# CAN2 register map
Registers from a debugger description file.
Registers are 32-bit, access not given, no defined reset value unless marked. A register's access mark holds for its fields unless they carry their own. Addresses are absolute; registers are grouped by the start of their names; lines under a group give offsets from that group; [hi:lo] are bit positions; {n}, {i} and the like mark numbered series; 'fields as' and 'values as' point back to an identical list; <NAME> marks a mode.

## CAN2
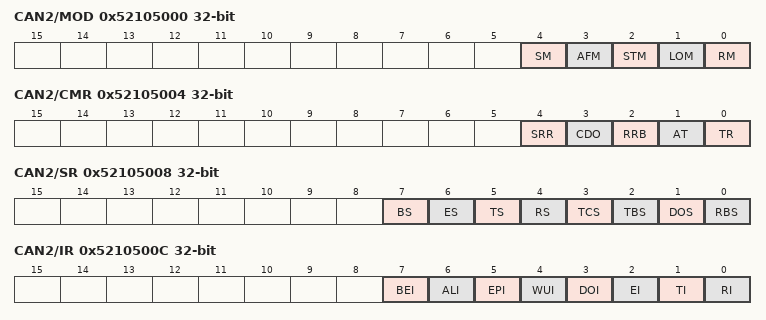
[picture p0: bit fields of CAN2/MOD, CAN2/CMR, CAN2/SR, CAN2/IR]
0x52105000 CAN2/MOD
  [4] SM, [3] AFM, [2] STM, [1] LOM, [0] RM
0x52105004 CAN2/CMR wo
  [4] SRR, [3] CDO, [2] RRB, [1] AT, [0] TR
0x52105008 CAN2/SR ro
  [7] BS, [6] ES, [5] TS, [4] RS, [3] TCS, [2] TBS, [1] DOS, [0] RBS
0x5210500C CAN2/IR ro
  [7] BEI, [6] ALI, [5] EPI, [4] WUI, [3] DOI, [2] EI, [1] TI, [0] RI
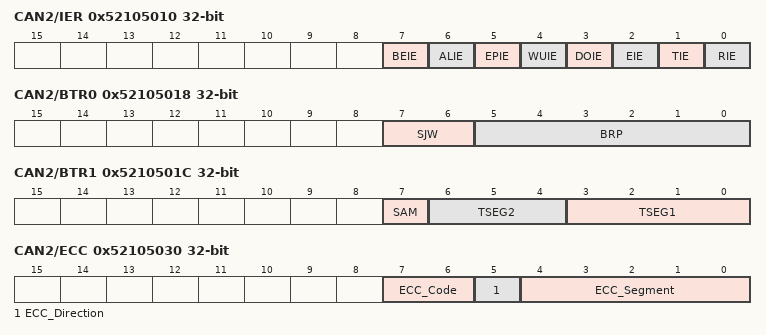
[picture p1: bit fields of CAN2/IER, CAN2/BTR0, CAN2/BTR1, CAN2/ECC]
0x52105010 CAN2/IER
  [7] BEIE, [6] ALIE, [5] EPIE, [4] WUIE, [3] DOIE, [2] EIE, [1] TIE, [0] RIE
0x52105018 CAN2/BTR0
  [7:6] SJW, [5:0] BRP
0x5210501C CAN2/BTR1
  [7] SAM, [6:4] TSEG2, [3:0] TSEG1
0x52105020 CAN2/OCR
  [1:0] OCMODE
0x5210502C CAN2/ALC ro
  [4:0] ALC
0x52105030 CAN2/ECC ro
  [7:6] ECC_Code, [5] ECC_Direction, [4:0] ECC_Segment
0x52105034 CAN2/EWLR
  [7:0] EWLR
0x52105038 CAN2/RXERR
  [7:0] RXERR
0x5210503C CAN2/TXERR
  [7:0] TXERR
{0x52105040+4i} CAN2/WrTransmitBuffer_{i} wo (i=0..12)
  [7:0] WrTransmitBuffer
{0x52105040+4i} CAN2/RdReceiveBuffer_{i} ro (i=0..12)
  [7:0] RdReceiveBuffer
{0x52105040+4i} CAN2/ACR{i} (i=0..3)
  [7:0] ACR
{0x52105050+4i} CAN2/AMR{i} (i=0..3)
  [7:0] AMR
0x52105074 CAN2/RMC ro
  [4:0] RMC
0x52105078 CAN2/RBSA
  [5:0] RBSA
{0x52105080+4i} CAN2/ReceiveFifo_{i} (i=0..63)
  [7:0] ReceiveFifo
{0x52105180+4i} CAN2/RdTransmitBuffer_{i} ro (i=0..12)
  [7:0] RdTransmitBuffer
{0x52105440+4i} CAN2/SyncTransmitBuffer_{i} (i=0..12)
  [7:0] SyncTransmitBuffer
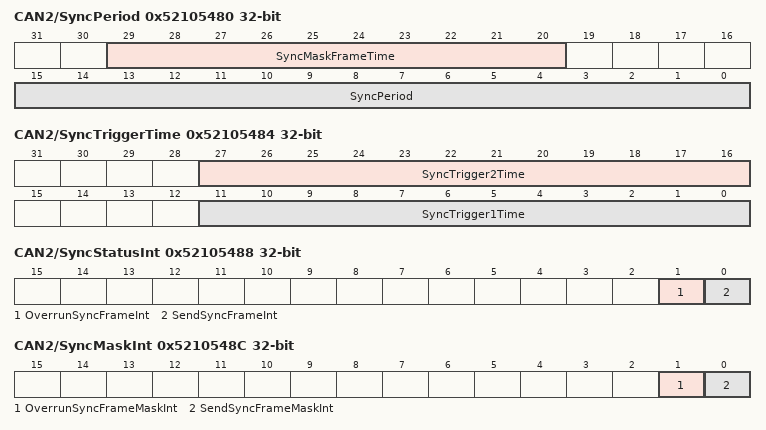
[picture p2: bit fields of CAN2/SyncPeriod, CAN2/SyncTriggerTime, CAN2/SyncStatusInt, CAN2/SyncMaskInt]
0x52105480 CAN2/SyncPeriod
  [29:20] SyncMaskFrameTime, [15:0] SyncPeriod
0x52105484 CAN2/SyncTriggerTime
  [27:16] SyncTrigger2Time, [11:0] SyncTrigger1Time
0x52105488 CAN2/SyncStatusInt ro
  [1] OverrunSyncFrameInt, [0] SendSyncFrameInt
0x5210548C CAN2/SyncMaskInt
  [1] OverrunSyncFrameMaskInt, [0] SendSyncFrameMaskInt
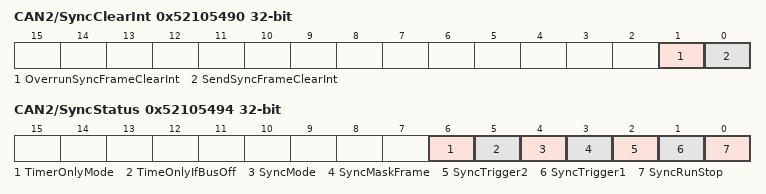
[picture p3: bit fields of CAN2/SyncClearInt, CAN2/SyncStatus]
0x52105490 CAN2/SyncClearInt
  [1] OverrunSyncFrameClearInt, [0] SendSyncFrameClearInt
0x52105494 CAN2/SyncStatus
  [6] TimerOnlyMode, [5] TimeOnlyIfBusOff, [4] SyncMode, [3] SyncMaskFrame ro, [2] SyncTrigger2 ro, [1] SyncTrigger1 ro, [0] SyncRunStop ro
0x52105498 CAN2/SyncClearSetRunStop wo
  [31:0] SyncClearSetRunStop
0x5210549C CAN2/SyncClearSetTrigger wo
  [31:0] SyncClearSetTrigger
0x521054A0 CAN2/SyncPassiveError
  [15:0] SyncPassiveError
